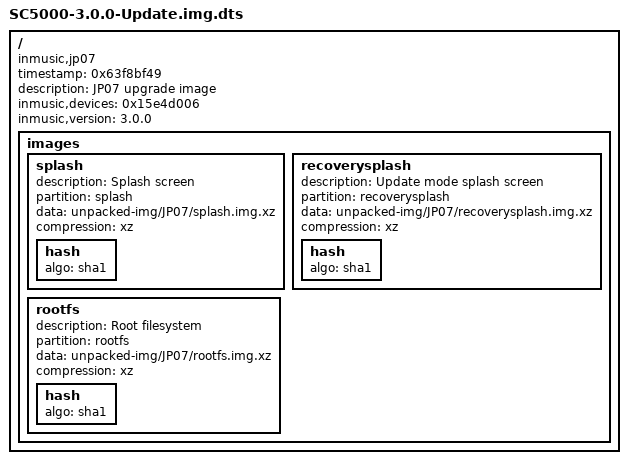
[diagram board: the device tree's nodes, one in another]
/dts-v1/;

/ {
	timestamp = <0x63f8bf49>;
	description = "JP07 upgrade image";
	compatible = "inmusic,jp07";
	inmusic,devices = <0x15e4d006>;
	inmusic,version = "3.0.0";

	images {

		splash {
			description = "Splash screen";
			partition = "splash";
			data = /incbin/("unpacked-img/JP07/splash.img.xz");
			compression = "xz";

			hash {
				algo = "sha1";
			};
		};

		recoverysplash {
			description = "Update mode splash screen";
			partition = "recoverysplash";
			data = /incbin/("unpacked-img/JP07/recoverysplash.img.xz");
			compression = "xz";

			hash {
				algo = "sha1";
			};
		};

		rootfs {
			description = "Root filesystem";
			partition = "rootfs";
			data = /incbin/("unpacked-img/JP07/rootfs.img.xz");
			compression = "xz";

			hash {
				algo = "sha1";
			};
		};
	};
};
